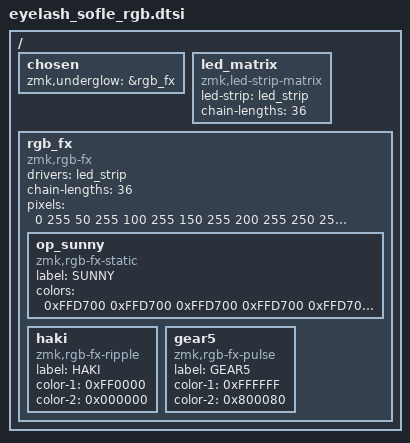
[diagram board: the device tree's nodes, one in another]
#include <dt-bindings/zmk/rgb_fx.h>

/ {
    chosen {
        zmk,underglow = &rgb_fx;
    };

    led_matrix: led_matrix {
        compatible = "zmk,led-strip-matrix";
        led-strip = <&led_strip>;
        chain-lengths = <36>;
    };

    rgb_fx: rgb_fx {
        compatible = "zmk,rgb-fx";
        drivers = <&led_strip>;
        chain-lengths = <36>;

        /* Satisfy 'pixels' requirement with a 6x6 grid mapping */
        pixels = <
            0   255  /* 0: UG */
            50  255  /* 1: UG */
            100 255  /* 2: UG */
            150 255  /* 3: UG */
            200 255  /* 4: UG */
            250 255  /* 5: UG */
            0   0    /* 6: ESC/` */
            20  0    /* 7: 1 */
            40  0    /* 8: 2 */
            60  0    /* 9: 3 */
            80  0    /* 10: 4 */
            100 0    /* 11: 5 */
            0   20   /* 12: Row 1... */
            20  20
            40  20
            60  20
            80  20
            100 20
            0   40   /* Row 2... */
            20  40
            40  40
            60  40
            80  40
            100 40
            0   60   /* Row 3... */
            20  60
            40  60
            60  60
            80  60
            100 60
            0   80   /* Row 4... */
            20  80
            40  80
            60  80
            80  80
            100 80
        >;

        op_sunny: op_sunny {
            compatible = "zmk,rgb-fx-static";
            label = "SUNNY";
            colors = <
                0xFFD700 0xFFD700 0xFFD700 0xFFD700 0xFFD700 0xFFD700 // 0-5: Underglow Gold
                0xFFD700                                             // 6: ESC/` Gold
                0xFF0000                                             // 7: 1 - Luffy Red
                0x00FF00                                             // 8: 2 - Zoro Green
                0xFFA500                                             // 9: 3 - Nami Orange
                0xFFFF00                                             // 10: 4 - Usopp Yellow
                0x0000FF                                             // 11: 5 - Sanji Blue
                0x000033 0x000033 0x000033 0x000033 0x000033 0x000033 // Row 1 Base
                0x000033 0x000033 0x000033 0x000033 0x000033 0x000033 // Row 2 Base
                0x000033 0x000033 0x000033 0x000033 0x000033 0x000033 // Row 3 Base
                0x000033 0x000033 0x000033 0x000033 0x000033 0x000033 // Row 4 Base
            >;
        };

        haki: haki {
            compatible = "zmk,rgb-fx-ripple";
            label = "HAKI";
            color-1 = <0xFF0000>;
            color-2 = <0x000000>;
        };

        gear5: gear5 {
            compatible = "zmk,rgb-fx-pulse";
            label = "GEAR5";
            color-1 = <0xFFFFFF>;
            color-2 = <0x800080>;
        };
    };
};
